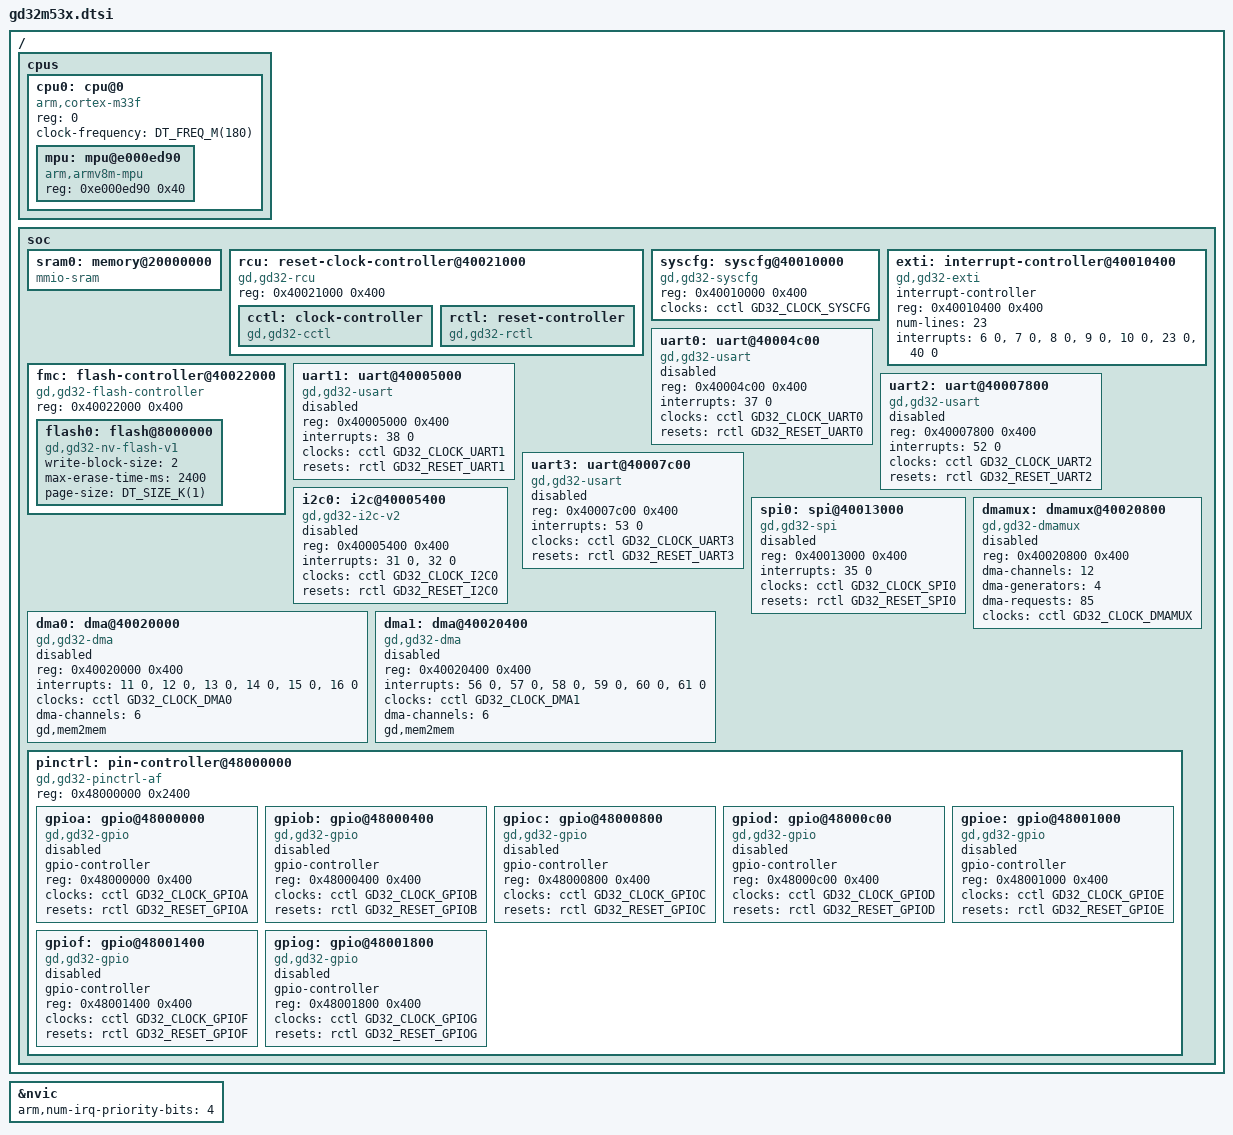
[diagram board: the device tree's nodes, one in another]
/*
 * Copyright (c) 2026 GigaDevice Semiconductor Inc.
 *
 * SPDX-License-Identifier: Apache-2.0
 */

#include <arm/armv8-m.dtsi>
#include <zephyr/dt-bindings/gpio/gpio.h>
#include <zephyr/dt-bindings/i2c/i2c.h>
#include <zephyr/dt-bindings/pwm/pwm.h>
#include <zephyr/dt-bindings/clock/gd32m53x-clocks.h>
#include <zephyr/dt-bindings/reset/gd32m53x.h>

/ {
	cpus {
		#address-cells = <1>;
		#size-cells = <0>;

		cpu0: cpu@0 {
			compatible = "arm,cortex-m33f";
			reg = <0>;
			#address-cells = <1>;
			#size-cells = <1>;
			clock-frequency = <DT_FREQ_M(180)>;

			mpu: mpu@e000ed90 {
				compatible = "arm,armv8m-mpu";
				reg = <0xe000ed90 0x40>;
			};
		};
	};

	soc {
		sram0: memory@20000000 {
			compatible = "mmio-sram";
		};

		rcu: reset-clock-controller@40021000 {
			compatible = "gd,gd32-rcu";
			reg = <0x40021000 0x400>;
			status = "okay";

			cctl: clock-controller {
				compatible = "gd,gd32-cctl";
				#clock-cells = <1>;
				status = "okay";
			};

			rctl: reset-controller {
				compatible = "gd,gd32-rctl";
				#reset-cells = <1>;
				status = "okay";
			};
		};

		syscfg: syscfg@40010000 {
			compatible = "gd,gd32-syscfg";
			reg = <0x40010000 0x400>;
			clocks = <&cctl GD32_CLOCK_SYSCFG>;
		};

		exti: interrupt-controller@40010400 {
			compatible = "gd,gd32-exti";
			interrupt-controller;
			#interrupt-cells = <1>;
			reg = <0x40010400 0x400>;
			num-lines = <23>;
			interrupts = <6 0>, <7 0>, <8 0>, <9 0>,
				     <10 0>, <23 0>, <40 0>;
			interrupt-names = "line0", "line1", "line2", "line3",
					  "line4", "line5-9", "line10-15";
			status = "okay";
		};

		fmc: flash-controller@40022000 {
			compatible = "gd,gd32-flash-controller";
			reg = <0x40022000 0x400>;

			#address-cells = <1>;
			#size-cells = <1>;

			flash0: flash@8000000 {
				compatible = "gd,gd32-nv-flash-v1", "soc-nv-flash";
				write-block-size = <2>;
				max-erase-time-ms = <2400>;
				page-size = <DT_SIZE_K(1)>;
			};
		};

		uart0: uart@40004c00 {
			compatible = "gd,gd32-usart";
			reg = <0x40004c00 0x400>;
			interrupts = <37 0>;
			clocks = <&cctl GD32_CLOCK_UART0>;
			resets = <&rctl GD32_RESET_UART0>;
			status = "disabled";
		};

		uart1: uart@40005000 {
			compatible = "gd,gd32-usart";
			reg = <0x40005000 0x400>;
			interrupts = <38 0>;
			clocks = <&cctl GD32_CLOCK_UART1>;
			resets = <&rctl GD32_RESET_UART1>;
			status = "disabled";
		};

		uart2: uart@40007800 {
			compatible = "gd,gd32-usart";
			reg = <0x40007800 0x400>;
			interrupts = <52 0>;
			clocks = <&cctl GD32_CLOCK_UART2>;
			resets = <&rctl GD32_RESET_UART2>;
			status = "disabled";
		};

		uart3: uart@40007c00 {
			compatible = "gd,gd32-usart";
			reg = <0x40007c00 0x400>;
			interrupts = <53 0>;
			clocks = <&cctl GD32_CLOCK_UART3>;
			resets = <&rctl GD32_RESET_UART3>;
			status = "disabled";
		};

		i2c0: i2c@40005400 {
			compatible = "gd,gd32-i2c-v2";
			reg = <0x40005400 0x400>;
			interrupts = <31 0>, <32 0>;
			interrupt-names = "event", "error";
			clocks = <&cctl GD32_CLOCK_I2C0>;
			resets = <&rctl GD32_RESET_I2C0>;
			#address-cells = <1>;
			#size-cells = <0>;
			status = "disabled";
		};

		spi0: spi@40013000 {
			compatible = "gd,gd32-spi";
			reg = <0x40013000 0x400>;
			interrupts = <35 0>;
			clocks = <&cctl GD32_CLOCK_SPI0>;
			resets = <&rctl GD32_RESET_SPI0>;
			#address-cells = <1>;
			#size-cells = <0>;
			status = "disabled";
		};

		dma0: dma@40020000 {
			compatible = "gd,gd32-dma";
			reg = <0x40020000 0x400>;
			interrupts = <11 0>, <12 0>, <13 0>,
				     <14 0>, <15 0>, <16 0>;
			clocks = <&cctl GD32_CLOCK_DMA0>;
			dma-channels = <6>;
			gd,mem2mem;
			#dma-cells = <2>;
			status = "disabled";
		};

		dma1: dma@40020400 {
			compatible = "gd,gd32-dma";
			reg = <0x40020400 0x400>;
			interrupts = <56 0>, <57 0>, <58 0>,
				     <59 0>, <60 0>, <61 0>;
			clocks = <&cctl GD32_CLOCK_DMA1>;
			dma-channels = <6>;
			gd,mem2mem;
			#dma-cells = <2>;
			status = "disabled";
		};

		dmamux: dmamux@40020800 {
			compatible = "gd,gd32-dmamux";
			reg = <0x40020800 0x400>;
			#dma-cells = <3>;
			dma-channels = <12>;
			dma-generators = <4>;
			dma-requests = <85>;
			clocks = <&cctl GD32_CLOCK_DMAMUX>;
			status = "disabled";
		};

		pinctrl: pin-controller@48000000 {
			compatible = "gd,gd32-pinctrl-af";
			reg = <0x48000000 0x2400>;
			#address-cells = <1>;
			#size-cells = <1>;

			gpioa: gpio@48000000 {
				compatible = "gd,gd32-gpio";
				gpio-controller;
				#gpio-cells = <2>;
				reg = <0x48000000 0x400>;
				clocks = <&cctl GD32_CLOCK_GPIOA>;
				resets = <&rctl GD32_RESET_GPIOA>;
				status = "disabled";
			};

			gpiob: gpio@48000400 {
				compatible = "gd,gd32-gpio";
				gpio-controller;
				#gpio-cells = <2>;
				reg = <0x48000400 0x400>;
				clocks = <&cctl GD32_CLOCK_GPIOB>;
				resets = <&rctl GD32_RESET_GPIOB>;
				status = "disabled";
			};

			gpioc: gpio@48000800 {
				compatible = "gd,gd32-gpio";
				gpio-controller;
				#gpio-cells = <2>;
				reg = <0x48000800 0x400>;
				clocks = <&cctl GD32_CLOCK_GPIOC>;
				resets = <&rctl GD32_RESET_GPIOC>;
				status = "disabled";
			};

			gpiod: gpio@48000c00 {
				compatible = "gd,gd32-gpio";
				gpio-controller;
				#gpio-cells = <2>;
				reg = <0x48000c00 0x400>;
				clocks = <&cctl GD32_CLOCK_GPIOD>;
				resets = <&rctl GD32_RESET_GPIOD>;
				status = "disabled";
			};

			gpioe: gpio@48001000 {
				compatible = "gd,gd32-gpio";
				gpio-controller;
				#gpio-cells = <2>;
				reg = <0x48001000 0x400>;
				clocks = <&cctl GD32_CLOCK_GPIOE>;
				resets = <&rctl GD32_RESET_GPIOE>;
				status = "disabled";
			};

			gpiof: gpio@48001400 {
				compatible = "gd,gd32-gpio";
				gpio-controller;
				#gpio-cells = <2>;
				reg = <0x48001400 0x400>;
				clocks = <&cctl GD32_CLOCK_GPIOF>;
				resets = <&rctl GD32_RESET_GPIOF>;
				status = "disabled";
			};

			gpiog: gpio@48001800 {
				compatible = "gd,gd32-gpio";
				gpio-controller;
				#gpio-cells = <2>;
				reg = <0x48001800 0x400>;
				clocks = <&cctl GD32_CLOCK_GPIOG>;
				resets = <&rctl GD32_RESET_GPIOG>;
				status = "disabled";
			};
		};
	};
};

&nvic {
	arm,num-irq-priority-bits = <4>;
};
